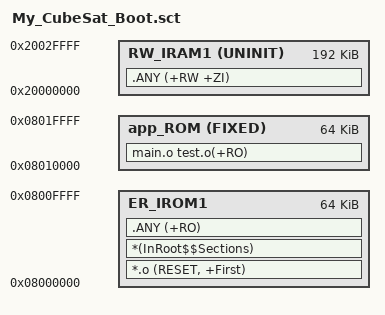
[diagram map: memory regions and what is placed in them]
; *************************************************************
; *** Scatter-Loading Description File generated by uVision ***
; *************************************************************

LR_IROM1 0x08000000 0x00020000  {    ; load region size_region
  ER_IROM1 0x08000000 0x00010000  {  ; load address = execution address
   *.o (RESET, +First)
   *(InRoot$$Sections)
   .ANY (+RO)
  }
  app_ROM 0x08010000 FIXED 0x00010000  {  ; load address = execution address
   main.o test.o(+RO)
  }
  RW_IRAM1 0x20000000 UNINIT 0x00030000  {  ; RW data
   .ANY (+RW +ZI)
  }
}

